# STM32G554 register map
File version: 2.0.0
CPU: CM33 r0p4, little endian, MPU, FPU, 4 interrupt priority bits
Registers are 32-bit, read-write, reset 0x0 unless marked. A register's access mark holds for its fields unless they carry their own. Offsets are from the block's base; [hi:lo] are bit positions.

## SBS — SBS address block description
Base 0x44000400
Same registers: SBS_S 0x54000400
0x10 SBS_HDPLCR reset 0xB4 — SBS temporal isolation control register
  [7:0] INCR_HDPL — increment HDPL value
    180=no increment; 106=recommended value to increment HDPL level by one
0x14 SBS_HDPLSR ro reset not defined — SBS temporal isolation status register
  [7:0] HDPL — temporal isolation level
    180=HDPL0, RSS; 81=HDPL1, iRoT; 138=HDPL2, uRoT; 111=HDPL3, application (secure/nonsecure)
0x18 SBS_NEXTHDPLCR — SBS next HDPL control register
  [1:0] NEXTHDPL — index to point to a higher HDPL than the current one
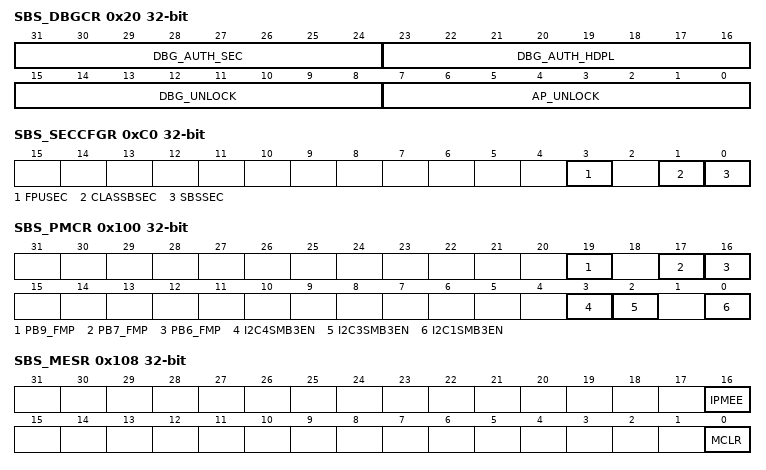
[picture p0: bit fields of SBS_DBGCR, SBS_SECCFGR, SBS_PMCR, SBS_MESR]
0x20 SBS_DBGCR — SBS debug control register
  [31:24] DBG_AUTH_SEC — control debug opening secure/nonsecure
  [23:16] DBG_AUTH_HDPL — authenticated debug temporal isolation level
    81=HDPL1; 138=HDPL2; 111=HDPL3
  [15:8] DBG_UNLOCK — debug unlock when DBG_AUTH_HDPL is reached
  [7:0] AP_UNLOCK — access port unlock
0x24 SBS_DBGLOCKR reset 0xB4 — SBS debug lock register
  [7:0] DBGCFG_LOCK — debug configuration lock
    180=Writes to SBS_DBGCR and SBS_DBGCR2 allowed (default)
0x28 SBS_DBGCR2 — SBS debug control register 2
  [7:0] SEC_AP_UNLOCK — Secure AHB access port unlock.
0x34 SBS_RSSCMDR — SBS RSS command register
  [15:0] RSSCMD — RSS command
0xA0 SBS_EPOCHSELCR — SBS EPOCH selection control register
  [1:0] EPOCH_SEL — select EPOCH value to be sent to the SAES
    0=NS_EPOCH (nonsecure) counter input selected; 1=SEC_EPOCH counter input selected
0xC0 SBS_SECCFGR — SBS security mode configuration control register
  [3] FPUSEC — FPU security enable
    0=SBS_FPUIMR register accessible through secure or nonsecure transaction; 1=SBS_FPUIMR register accessible only through secure transaction
  [1] CLASSBSEC — ClassB security enable
    0=SBS_CFGR2 register accessible through secure or nonsecure transaction; 1=SBS_CFGR2 register accessible only through secure transaction
  [0] SBSSEC — SBS clock control, memory-erase status register and compensation cell register security enable
    0=SBS_MESR, SBS_CCCSR, SBS_CCVALR, SBS_CCSWCR registers accessible through secure or nonsecure transaction; 1=SBS_MESR, SBS_CCCSR, SBS_CCVALR, SBS_CCSWCR registers accessible only through secure transaction
0x100 SBS_PMCR — SBS product mode and configuration register
  [19] PB9_FMP — Fast-mode Plus driving capability activation on PB9
    0=PB9 pin operates in standard mode; 1=Fm+ mode is enabled on PB9 pin and the speed control is bypassed
  [17] PB7_FMP — Fast-mode Plus driving capability activation on PB7
    0=PB7 pin operates in standard mode; 1=Fm+ mode is enabled on PB7 pin and the speed control is bypassed
  [16] PB6_FMP — Fast-mode Plus driving capability activation on PB6
    0=PB6 pin operates in standard mode; 1=Fm+ mode is enabled on PB6 pin and the speed control is bypassed
  [3] I2C4SMB3EN — SMBUS 3.0 on I2C4 enable
    0=SMBUS 3.0 on I2C4 enable; 1=SMBUS 3.0 on I2C4 enable
  [2] I2C3SMB3EN — SMBUS 3.0 on I2C3 enable
    0=SMBUS 3.0 on I2C3 enable; 1=SMBUS 3.0 on I2C3 enable
  [0] I2C1SMB3EN — SMBUS 3.0 on I2C1 enable
    0=SMBUS 3.0 on I2C1 enable; 1=SMBUS 3.0 on I2C1 enable
0x104 SBS_FPUIMR reset 0x1F — SBS FPU interrupt mask register
  [5:0] FPU_IE — FPU interrupt enable
0x108 SBS_MESR (reset mask 0xFFFFFFF0) — SBS memory erase status register
  [16] IPMEE — ICACHE erase status
    0=ICACHE and PKA RAM erase on going; 1=ICACHE and PKA RAM erase done
  [0] MCLR — device memories erase status
    0=memory erase on going if not yet cleared by software; 1=Memory erase done
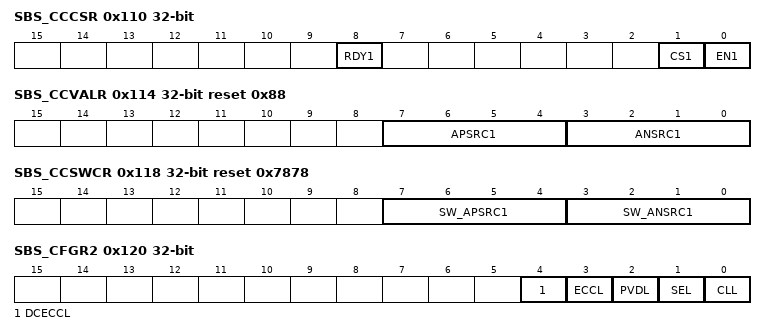
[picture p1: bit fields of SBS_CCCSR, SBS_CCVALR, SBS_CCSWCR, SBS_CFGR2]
0x110 SBS_CCCSR — SBS compensation cell for I/Os control and status register
  [8] RDY1 ro — VDD compensation cell ready flag
    0=VDD compensation cell not ready; 1=VDD compensation cell ready (code value provided by the cell can be used)
  [1] CS1 — code selection for VDD power rail (reset value set to 1)
    0=Code from the cell (available in the SBS_CCVALR); 1=Code from SBS_CCSWCR
  [0] EN1 — enable compensation cell for VDD power rail
    0=I/O compensation cell disabled; 1=I/O compensation cell enabled
0x114 SBS_CCVALR ro reset 0x88 — SBS compensation cell for I/Os value register
  [7:4] APSRC1 — compensation value for the PMOS transistor
  [3:0] ANSRC1 — compensation value for the NMOS transistor
0x118 SBS_CCSWCR reset 0x7878 — SBS compensation cell for I/Os software code register
  [7:4] SW_APSRC1 — PMOS compensation code for the VDD power rails
  [3:0] SW_ANSRC1 — NMOS compensation code for VDD power rails
0x120 SBS_CFGR2 — SBS Class B register
  [4] DCECCL — Arm Cortex -M33 D-CACHE ECC lock
    0=Arm Cortex -M33 D-CACHE double ECC error flag disconnected to timer break inputs; 1=Arm Cortex -M33 D-CACHE double ECC error flag connected to timer break inputs
  [3] ECCL — ECC lock
    0=double ECC error flag disconnected to timer break inputs; 1=double ECC error flag connected to timer break inputs
  [2] PVDL — PVD lock
    0=PVD interrupt disconnected from timer break inputs. PVDE and PLS[2:0] in the PWR registers are read/write; 1=PVD interrupt is connected to timer break inputs. PVDE and PLS[2:0] in the PWR registers are read only
  [1] SEL — SRAM ECC error lock
    0=SRAM double ECC error flag disconnected from timer break inputs; 1=SRAM double ECC error flag connected to timer break inputs
  [0] CLL — core lockup lock
    0=lockup output disconnected from timer break inputs; 1=lockup output connected to timer break inputs
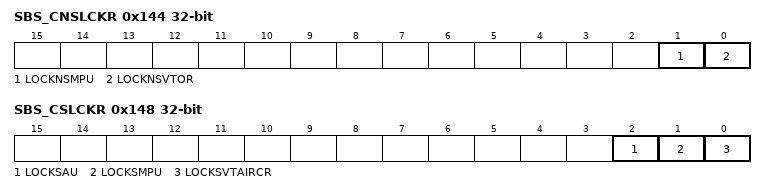
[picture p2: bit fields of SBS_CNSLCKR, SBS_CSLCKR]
0x144 SBS_CNSLCKR — SBS CPU nonsecure lock register
  [1] LOCKNSMPU — nonsecure MPU register lock
    0=nonsecure MPU registers write enabled; 1=nonsecure MPU registers write disabled
  [0] LOCKNSVTOR — VTOR_NS register lock
    0=VTOR_NS register write enabled; 1=VTOR_NS register write disabled
0x148 SBS_CSLCKR — SBS CPU secure lock register
  [2] LOCKSAU — SAU registers lock
    0=SAU registers write enabled; 1=SAU registers write disabled
  [1] LOCKSMPU — secure MPU registers lock
    0=Secure MPU registers writes enabled; 1=Secure MPU registers writes disabled
  [0] LOCKSVTAIRCR — VTOR_S and AIRCR register lock
    0=VTOR_S register PRIS and BFHFNMINS bits in the AIRCR register write enabled; 1=VTOR_S register PRIS and BFHFNMINS bits in the AIRCR register write disabled
0x14C SBS_ECCNMIR — SBS ECC NMI mask register
  [0] ECCNMI_MASK_EN — NMI behavior setup when a double ECC error occurs on FLASH data part
    0=NMI generated if a double ECC error in the FLASH data part; 1=NMI not generated if a double ECC error in the FLASH data part
0x170 SBS_SWAPLOCKR reset 0xB4 — SBS debug control register 2
  [7:0] SWAP_LOCK — Flash bank swap operation lock
    195=Flash bank swap operation allowed, FB_MODE and SWAP_BANK option byte can be modified; 180=Flash bank swap operation not allowed, FB_MODE and SWAP_BANK option byte access blocked
0x174 SBS_FBMODER reset 0xC3 — SBS debug control register 2
  [7:0] FB_MODE — Flash bank mode selection
    195=Flash Bank 1 mapped at 0x0800 0000 (and aliased @0x0C00 0000) and Flash Bank 2 mapped at 0x0804 0000 (and aliased at 0x0C04 0000); 180=Flash Bank 2 mapped at 0x0800 0000 (and aliased @0x0C00 0000) and Flash Bank 1 mapped at 0x0804 0000 (and aliased at 0x0C04 0000)
